AUTOSAR XML (schema 4-0-3)
standard types defined: Boolean, UInt16, UInt32
package /AUTOSAR_Platform/DataConstrs
  range DC_Boolean: raw 0..1
  range DC_UInt16: raw 0..65535
package /PATAC/MSM/ComponentTypes
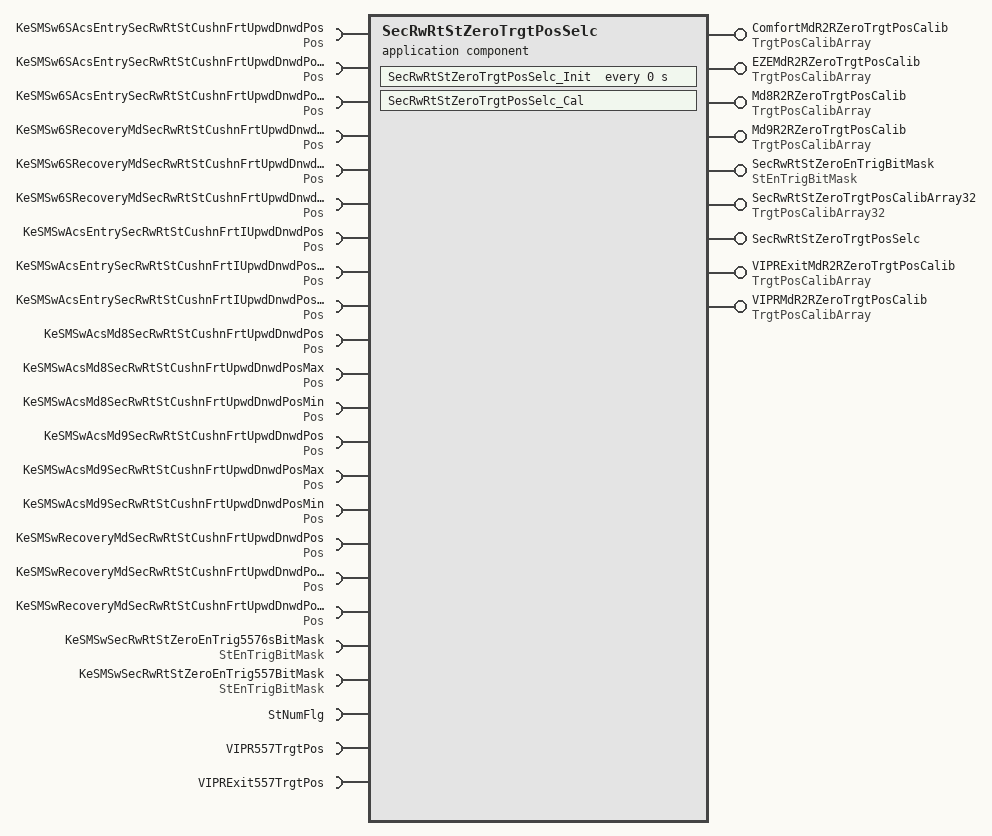
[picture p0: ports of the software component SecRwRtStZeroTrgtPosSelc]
  application sw component type SecRwRtStZeroTrgtPosSelc
    9 x provide port:
      ComfortMdR2RZeroTrgtPosCalib: nonqueued-sender-com-spec{data-element=TrgtPosArray, init-value=[4095, 4095, 4095]}, provided-interface=TrgtPosCalibArray
      EZEMdR2RZeroTrgtPosCalib: nonqueued-sender-com-spec{data-element=TrgtPosArray, init-value=[4095, 4095, 4095]}, provided-interface=TrgtPosCalibArray
      Md8R2RZeroTrgtPosCalib: nonqueued-sender-com-spec{data-element=TrgtPosArray, init-value=[4095, 4095, 4095]}, provided-interface=TrgtPosCalibArray
      Md9R2RZeroTrgtPosCalib: nonqueued-sender-com-spec{data-element=TrgtPosArray, init-value=[4095, 4095, 4095]}, provided-interface=TrgtPosCalibArray
      SecRwRtStZeroEnTrigBitMask: nonqueued-sender-com-spec{data-element=Val, init-value=0}, provided-interface=StEnTrigBitMask
      SecRwRtStZeroTrgtPosCalibArray32: nonqueued-sender-com-spec{data-element=TrgtPosArray32, init-value=96 x 4095}, provided-interface=TrgtPosCalibArray32
      SecRwRtStZeroTrgtPosSelc: server-com-spec{operation=Cal, queue-length=1}, provided-interface=SecRwRtStZeroTrgtPosSelc
      VIPRExitMdR2RZeroTrgtPosCalib: nonqueued-sender-com-spec{data-element=TrgtPosArray, init-value=[4095, 4095, 4095]}, provided-interface=TrgtPosCalibArray
      VIPRMdR2RZeroTrgtPosCalib: nonqueued-sender-com-spec{data-element=TrgtPosArray, init-value=[4095, 4095, 4095]}, provided-interface=TrgtPosCalibArray
    23 x require port:
      KeSMSw6SAcsEntrySecRwRtStCushnFrtUpwdDnwdPos: parameter-require-com-spec{init-value=0, parameter=Pos/Val}, required-interface=Pos
      KeSMSw6SAcsEntrySecRwRtStCushnFrtUpwdDnwdPosMax: parameter-require-com-spec{init-value=0, parameter=Pos/Val}, required-interface=Pos
      KeSMSw6SAcsEntrySecRwRtStCushnFrtUpwdDnwdPosMin: parameter-require-com-spec{init-value=0, parameter=Pos/Val}, required-interface=Pos
      KeSMSw6SRecoveryMdSecRwRtStCushnFrtUpwdDnwdPos: parameter-require-com-spec{init-value=0, parameter=Pos/Val}, required-interface=Pos
      KeSMSw6SRecoveryMdSecRwRtStCushnFrtUpwdDnwdPosMax: parameter-require-com-spec{init-value=0, parameter=Pos/Val}, required-interface=Pos
      KeSMSw6SRecoveryMdSecRwRtStCushnFrtUpwdDnwdPosMin: parameter-require-com-spec{init-value=0, parameter=Pos/Val}, required-interface=Pos
      KeSMSwAcsEntrySecRwRtStCushnFrtIUpwdDnwdPos: parameter-require-com-spec{init-value=0, parameter=Pos/Val}, required-interface=Pos
      KeSMSwAcsEntrySecRwRtStCushnFrtIUpwdDnwdPosMax: parameter-require-com-spec{init-value=0, parameter=Pos/Val}, required-interface=Pos
      KeSMSwAcsEntrySecRwRtStCushnFrtIUpwdDnwdPosMin: parameter-require-com-spec{init-value=0, parameter=Pos/Val}, required-interface=Pos
      KeSMSwAcsMd8SecRwRtStCushnFrtUpwdDnwdPos: parameter-require-com-spec{init-value=0, parameter=Pos/Val}, required-interface=Pos
      KeSMSwAcsMd8SecRwRtStCushnFrtUpwdDnwdPosMax: parameter-require-com-spec{init-value=0, parameter=Pos/Val}, required-interface=Pos
      KeSMSwAcsMd8SecRwRtStCushnFrtUpwdDnwdPosMin: parameter-require-com-spec{init-value=0, parameter=Pos/Val}, required-interface=Pos
      KeSMSwAcsMd9SecRwRtStCushnFrtUpwdDnwdPos: parameter-require-com-spec{init-value=0, parameter=Pos/Val}, required-interface=Pos
      KeSMSwAcsMd9SecRwRtStCushnFrtUpwdDnwdPosMax: parameter-require-com-spec{init-value=0, parameter=Pos/Val}, required-interface=Pos
      KeSMSwAcsMd9SecRwRtStCushnFrtUpwdDnwdPosMin: parameter-require-com-spec{init-value=0, parameter=Pos/Val}, required-interface=Pos
      KeSMSwRecoveryMdSecRwRtStCushnFrtUpwdDnwdPos: parameter-require-com-spec{init-value=0, parameter=Pos/Val}, required-interface=Pos
      KeSMSwRecoveryMdSecRwRtStCushnFrtUpwdDnwdPosMax: parameter-require-com-spec{init-value=0, parameter=Pos/Val}, required-interface=Pos
      KeSMSwRecoveryMdSecRwRtStCushnFrtUpwdDnwdPosMin: parameter-require-com-spec{init-value=0, parameter=Pos/Val}, required-interface=Pos
      KeSMSwSecRwRtStZeroEnTrig5576sBitMask: parameter-require-com-spec{init-value=6153, parameter=StEnTrigBitMask/Val}, required-interface=StEnTrigBitMask
      KeSMSwSecRwRtStZeroEnTrig557BitMask: parameter-require-com-spec{init-value=6153, parameter=StEnTrigBitMask/Val}, required-interface=StEnTrigBitMask
      StNumFlg: required-interface=StNumFlg
        required-com-specs:
          data-element=Is4s, filter=data-filter-type=ALWAYS, init-value=0
          data-element=Is6s, filter=data-filter-type=ALWAYS, init-value=0
          data-element=Is6s7s, filter=data-filter-type=ALWAYS, init-value=0
          data-element=Is7s, filter=data-filter-type=ALWAYS, init-value=0
      VIPR557TrgtPos: required-com-specs=[VIPR557TrgtPos/Get, VIPR557TrgtPos/Set], required-interface=VIPR557TrgtPos
      VIPRExit557TrgtPos: required-com-specs=[VIPRExit557TrgtPos/Get, VIPRExit557TrgtPos/Set], required-interface=VIPRExit557TrgtPos
    behavior SecRwRtStZeroTrgtPosSelc_InternalBehavior
      operation invoked event OIT_SecRwRtStZeroTrgtPosSelc_Cal_SecRwRtStZeroTrgtPosSelc_Cal: start-on-event=SecRwRtStZeroTrgtPosSelc_Cal, operation=SecRwRtStZeroTrgtPosSelc.Cal
      timing event SecRwRtStZeroTrgtPosSelc_InitEvent: start-on-event=SecRwRtStZeroTrgtPosSelc_Init, period=0
      runnable SecRwRtStZeroTrgtPosSelc_Cal
        data-receive-point-by-arguments:
          4 x access:
            REC_StNumFlg_Is4s: accessed-variable=StNumFlg.Is4s
            REC_StNumFlg_Is6s: accessed-variable=StNumFlg.Is6s
            REC_StNumFlg_Is6s7s: accessed-variable=StNumFlg.Is6s7s
            REC_StNumFlg_Is7s: accessed-variable=StNumFlg.Is7s
        data-send-points:
          8 x access:
            SEND_ComfortMdR2RZeroTrgtPosCalib_TrgtPosArray: accessed-variable=ComfortMdR2RZeroTrgtPosCalib.TrgtPosArray
            SEND_EZEMdR2RZeroTrgtPosCalib_TrgtPosArray: accessed-variable=EZEMdR2RZeroTrgtPosCalib.TrgtPosArray
            SEND_Md8R2RZeroTrgtPosCalib_TrgtPosArray: accessed-variable=Md8R2RZeroTrgtPosCalib.TrgtPosArray
            SEND_Md9R2RZeroTrgtPosCalib_TrgtPosArray: accessed-variable=Md9R2RZeroTrgtPosCalib.TrgtPosArray
            SEND_SecRwRtStZeroEnTrigBitMask_Val: accessed-variable=SecRwRtStZeroEnTrigBitMask.Val
            SEND_SecRwRtStZeroTrgtPosCalibArray32_TrgtPosArray32: accessed-variable=SecRwRtStZeroTrgtPosCalibArray32.TrgtPosArray32
            SEND_VIPRExitMdR2RZeroTrgtPosCalib_TrgtPosArray: accessed-variable=VIPRExitMdR2RZeroTrgtPosCalib.TrgtPosArray
            SEND_VIPRMdR2RZeroTrgtPosCalib_TrgtPosArray: accessed-variable=VIPRMdR2RZeroTrgtPosCalib.TrgtPosArray
        20 x parameter access:
          PA_KeSMSw6SAcsEntrySecRwRtStCushnFrtUpwdDnwdPos_Val: accessed-parameter=KeSMSw6SAcsEntrySecRwRtStCushnFrtUpwdDnwdPos.Val
          PA_KeSMSw6SAcsEntrySecRwRtStCushnFrtUpwdDnwdPosMax_Val: accessed-parameter=KeSMSw6SAcsEntrySecRwRtStCushnFrtUpwdDnwdPosMax.Val
          PA_KeSMSw6SAcsEntrySecRwRtStCushnFrtUpwdDnwdPosMin_Val: accessed-parameter=KeSMSw6SAcsEntrySecRwRtStCushnFrtUpwdDnwdPosMin.Val
          PA_KeSMSw6SRecoveryMdSecRwRtStCushnFrtUpwdDnwdPos_Val: accessed-parameter=KeSMSw6SRecoveryMdSecRwRtStCushnFrtUpwdDnwdPos.Val
          PA_KeSMSw6SRecoveryMdSecRwRtStCushnFrtUpwdDnwdPosMax_Val: accessed-parameter=KeSMSw6SRecoveryMdSecRwRtStCushnFrtUpwdDnwdPosMax.Val
          PA_KeSMSw6SRecoveryMdSecRwRtStCushnFrtUpwdDnwdPosMin_Val: accessed-parameter=KeSMSw6SRecoveryMdSecRwRtStCushnFrtUpwdDnwdPosMin.Val
          PA_KeSMSwAcsEntrySecRwRtStCushnFrtIUpwdDnwdPos_Val: accessed-parameter=KeSMSwAcsEntrySecRwRtStCushnFrtIUpwdDnwdPos.Val
          PA_KeSMSwAcsEntrySecRwRtStCushnFrtIUpwdDnwdPosMax_Val: accessed-parameter=KeSMSwAcsEntrySecRwRtStCushnFrtIUpwdDnwdPosMax.Val
          PA_KeSMSwAcsEntrySecRwRtStCushnFrtIUpwdDnwdPosMin_Val: accessed-parameter=KeSMSwAcsEntrySecRwRtStCushnFrtIUpwdDnwdPosMin.Val
          PA_KeSMSwAcsMd8SecRwRtStCushnFrtUpwdDnwdPos_Val: accessed-parameter=KeSMSwAcsMd8SecRwRtStCushnFrtUpwdDnwdPos.Val
          PA_KeSMSwAcsMd8SecRwRtStCushnFrtUpwdDnwdPosMax_Val: accessed-parameter=KeSMSwAcsMd8SecRwRtStCushnFrtUpwdDnwdPosMax.Val
          PA_KeSMSwAcsMd8SecRwRtStCushnFrtUpwdDnwdPosMin_Val: accessed-parameter=KeSMSwAcsMd8SecRwRtStCushnFrtUpwdDnwdPosMin.Val
          PA_KeSMSwAcsMd9SecRwRtStCushnFrtUpwdDnwdPos_Val: accessed-parameter=KeSMSwAcsMd9SecRwRtStCushnFrtUpwdDnwdPos.Val
          PA_KeSMSwAcsMd9SecRwRtStCushnFrtUpwdDnwdPosMax_Val: accessed-parameter=KeSMSwAcsMd9SecRwRtStCushnFrtUpwdDnwdPosMax.Val
          PA_KeSMSwAcsMd9SecRwRtStCushnFrtUpwdDnwdPosMin_Val: accessed-parameter=KeSMSwAcsMd9SecRwRtStCushnFrtUpwdDnwdPosMin.Val
          PA_KeSMSwRecoveryMdSecRwRtStCushnFrtUpwdDnwdPos_Val: accessed-parameter=KeSMSwRecoveryMdSecRwRtStCushnFrtUpwdDnwdPos.Val
          PA_KeSMSwRecoveryMdSecRwRtStCushnFrtUpwdDnwdPosMax_Val: accessed-parameter=KeSMSwRecoveryMdSecRwRtStCushnFrtUpwdDnwdPosMax.Val
          PA_KeSMSwRecoveryMdSecRwRtStCushnFrtUpwdDnwdPosMin_Val: accessed-parameter=KeSMSwRecoveryMdSecRwRtStCushnFrtUpwdDnwdPosMin.Val
          PA_KeSMSwSecRwRtStZeroEnTrig5576sBitMask_Val: accessed-parameter=KeSMSwSecRwRtStZeroEnTrig5576sBitMask.Val
          PA_KeSMSwSecRwRtStZeroEnTrig557BitMask_Val: accessed-parameter=KeSMSwSecRwRtStZeroEnTrig557BitMask.Val
        sync call SC_VIPR557TrgtPos_Get: operation=VIPR557TrgtPos.Get, timeout=0
        sync call SC_VIPRExit557TrgtPos_Get: operation=VIPRExit557TrgtPos.Get, timeout=0
      runnable SecRwRtStZeroTrgtPosSelc_Init
        20 x parameter access:
          PA_KeSMSw6SAcsEntrySecRwRtStCushnFrtUpwdDnwdPos_Val: accessed-parameter=KeSMSw6SAcsEntrySecRwRtStCushnFrtUpwdDnwdPos.Val
          PA_KeSMSw6SAcsEntrySecRwRtStCushnFrtUpwdDnwdPosMax_Val: accessed-parameter=KeSMSw6SAcsEntrySecRwRtStCushnFrtUpwdDnwdPosMax.Val
          PA_KeSMSw6SAcsEntrySecRwRtStCushnFrtUpwdDnwdPosMin_Val: accessed-parameter=KeSMSw6SAcsEntrySecRwRtStCushnFrtUpwdDnwdPosMin.Val
          PA_KeSMSw6SRecoveryMdSecRwRtStCushnFrtUpwdDnwdPos_Val: accessed-parameter=KeSMSw6SRecoveryMdSecRwRtStCushnFrtUpwdDnwdPos.Val
          PA_KeSMSw6SRecoveryMdSecRwRtStCushnFrtUpwdDnwdPosMax_Val: accessed-parameter=KeSMSw6SRecoveryMdSecRwRtStCushnFrtUpwdDnwdPosMax.Val
          PA_KeSMSw6SRecoveryMdSecRwRtStCushnFrtUpwdDnwdPosMin_Val: accessed-parameter=KeSMSw6SRecoveryMdSecRwRtStCushnFrtUpwdDnwdPosMin.Val
          PA_KeSMSwAcsEntrySecRwRtStCushnFrtIUpwdDnwdPos_Val: accessed-parameter=KeSMSwAcsEntrySecRwRtStCushnFrtIUpwdDnwdPos.Val
          PA_KeSMSwAcsEntrySecRwRtStCushnFrtIUpwdDnwdPosMax_Val: accessed-parameter=KeSMSwAcsEntrySecRwRtStCushnFrtIUpwdDnwdPosMax.Val
          PA_KeSMSwAcsEntrySecRwRtStCushnFrtIUpwdDnwdPosMin_Val: accessed-parameter=KeSMSwAcsEntrySecRwRtStCushnFrtIUpwdDnwdPosMin.Val
          PA_KeSMSwAcsMd8SecRwRtStCushnFrtUpwdDnwdPos_Val: accessed-parameter=KeSMSwAcsMd8SecRwRtStCushnFrtUpwdDnwdPos.Val
          PA_KeSMSwAcsMd8SecRwRtStCushnFrtUpwdDnwdPosMax_Val: accessed-parameter=KeSMSwAcsMd8SecRwRtStCushnFrtUpwdDnwdPosMax.Val
          PA_KeSMSwAcsMd8SecRwRtStCushnFrtUpwdDnwdPosMin_Val: accessed-parameter=KeSMSwAcsMd8SecRwRtStCushnFrtUpwdDnwdPosMin.Val
          PA_KeSMSwAcsMd9SecRwRtStCushnFrtUpwdDnwdPos_Val: accessed-parameter=KeSMSwAcsMd9SecRwRtStCushnFrtUpwdDnwdPos.Val
          PA_KeSMSwAcsMd9SecRwRtStCushnFrtUpwdDnwdPosMax_Val: accessed-parameter=KeSMSwAcsMd9SecRwRtStCushnFrtUpwdDnwdPosMax.Val
          PA_KeSMSwAcsMd9SecRwRtStCushnFrtUpwdDnwdPosMin_Val: accessed-parameter=KeSMSwAcsMd9SecRwRtStCushnFrtUpwdDnwdPosMin.Val
          PA_KeSMSwRecoveryMdSecRwRtStCushnFrtUpwdDnwdPos_Val: accessed-parameter=KeSMSwRecoveryMdSecRwRtStCushnFrtUpwdDnwdPos.Val
          PA_KeSMSwRecoveryMdSecRwRtStCushnFrtUpwdDnwdPosMax_Val: accessed-parameter=KeSMSwRecoveryMdSecRwRtStCushnFrtUpwdDnwdPosMax.Val
          PA_KeSMSwRecoveryMdSecRwRtStCushnFrtUpwdDnwdPosMin_Val: accessed-parameter=KeSMSwRecoveryMdSecRwRtStCushnFrtUpwdDnwdPosMin.Val
          PA_KeSMSwSecRwRtStZeroEnTrig5576sBitMask_Val: accessed-parameter=KeSMSwSecRwRtStZeroEnTrig5576sBitMask.Val
          PA_KeSMSwSecRwRtStZeroEnTrig557BitMask_Val: accessed-parameter=KeSMSwSecRwRtStZeroEnTrig557BitMask.Val
  swc implementation SecRwRtStZeroTrgtPosSelc_Implementation: behavior=SecRwRtStZeroTrgtPosSelc_InternalBehavior
    code-descriptors:
      code Default: artifact-descriptors=autosar-engineering-object={short-label=Default, category=SWSRC}
package /PATAC/MSM/ModeAdjust/CalPortInterface
  parameter interface Pos
    parameter data prototype Val: sw-calibration-access=READ-WRITE, type=UInt16
  parameter interface StEnTrigBitMask
    parameter data prototype Val: sw-calibration-access=READ-WRITE, type=UInt32
package /PATAC/MSM/ModeAdjust/DataType
  impl type TrgtPosCalibArray: category=ARRAY, sw-calibration-access=READ-ONLY, type-emitter=RTE  # 0:pos 1:max 2:min
    element Element: array-size=3, array-size-semantics=FIXED-SIZE, implementation-data-type=UInt16, invalid-value=0
  impl type TrgtPosCalibArray32: category=ARRAY, sw-calibration-access=READ-ONLY, type-emitter=RTE  # 0:pos 1:max 2:min
    element Element: array-size=96, array-size-semantics=FIXED-SIZE, implementation-data-type=UInt16, invalid-value=0
package /PATAC/MSM/ModeAdjust/PortInterface
  client server interface SecRwRtStZeroTrgtPosSelc
    operation Cal
  client server interface VIPR557TrgtPos
    operation Get
      5 x arg, all with type=UInt16, direction=OUT, server-argument-impl-policy=USE-ARGUMENT-TYPE:
        SecRwLtStBkReclnTrgtPos
        SecRwLtStZeroTrgtPos
        SecRwLtStLgrstUpwdDnwdTrgtPos
        SecRwLtStLgrstInwdOtwdTrgtPos
        SecRwLtStFwdBkwdTrgtPos
    operation Set
      5 x arg, all with type=UInt16, direction=IN, server-argument-impl-policy=USE-ARGUMENT-TYPE:
        SecRwLtStBkReclnTrgtPos
        SecRwLtStZeroTrgtPos
        SecRwLtStLgrstUpwdDnwdTrgtPos
        SecRwLtStLgrstInwdOtwdTrgtPos
        SecRwLtStFwdBkwdTrgtPos
  client server interface VIPRExit557TrgtPos
    operation Get
      11 x arg, all with type=UInt16, direction=OUT, server-argument-impl-policy=USE-ARGUMENT-TYPE:
        SecRwRtStBkReclnTrgtPos
        SecRwRtStZeroTrgtPos
        SecRwRtStLgrstUpwdDnwdTrgtPos
        SecRwRtStLgrstInwdOtwdTrgtPos
        ThdRwLtStBkReclnTrgtPos
        ThdRwLtStFwdBkwdTrgtPos
        ThdRwRtStBkReclnTrgtPos
        ThdRwRtStFwdBkwdTrgtPos
        PassStBkReclnTrgtPos
        PassStFwdBkwdTrgtPos
        SecRwRtStFwdBkwdTrgtPos
    operation Set
  4 x sender receiver interface:
    StEnTrigBitMask: invalidation-policy{data-element=Val, handle-invalid=DONT-INVALIDATE}
      data Val: type=UInt32
    StNumFlg
      4 x data, all with type=Boolean:
        Is4s
        Is6s
        Is6s7s
        Is7s
      invalidation-policys:
        data-element=Is4s, handle-invalid=DONT-INVALIDATE
        data-element=Is6s, handle-invalid=DONT-INVALIDATE
        data-element=Is6s7s, handle-invalid=DONT-INVALIDATE
        data-element=Is7s, handle-invalid=DONT-INVALIDATE
    TrgtPosCalibArray: invalidation-policy{data-element=TrgtPosArray, handle-invalid=DONT-INVALIDATE}
      data TrgtPosArray: type=TrgtPosCalibArray  # 0:Pos 1:Max 2:Min
    TrgtPosCalibArray32: invalidation-policy{data-element=TrgtPosArray32, handle-invalid=DONT-INVALIDATE}
      data TrgtPosArray32: type=TrgtPosCalibArray32  # 0:Pos 1:Max 2:Min
